# ADC14_356.0 register map
Vendor: Texas Instruments
Peripheral module from a debugger description file (folder MSP432).
Registers are 32-bit, read-write, no defined reset value unless marked. A register's access mark holds for its fields unless they carry their own. Offsets are as the file gives them; lines under a group give offsets from that group; [hi:lo] are bit positions; {n}, {i} and the like mark numbered series; 'fields as' and 'values as' point back to an identical list; <NAME> marks a mode.

## ADC14
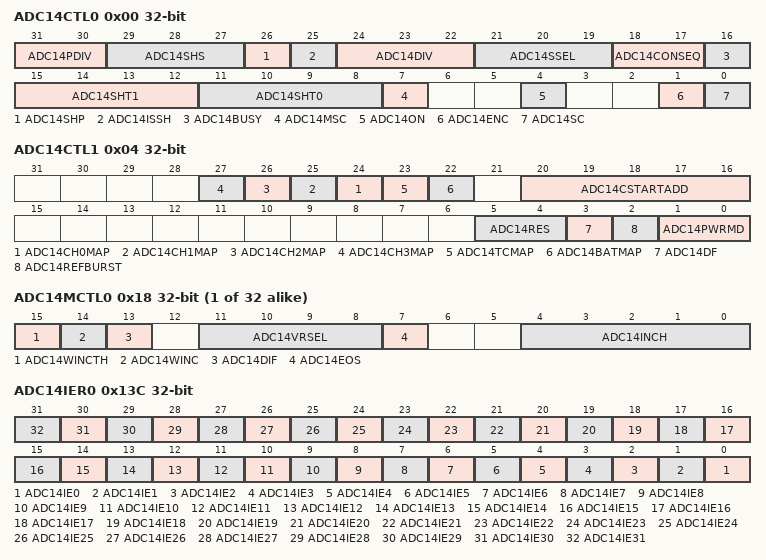
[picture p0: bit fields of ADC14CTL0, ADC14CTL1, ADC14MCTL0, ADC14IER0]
0x00 ADC14CTL0 access per field — Control 0 Register
  [31:30] ADC14PDIV rw — ADC14 predivider
    0=Predivide by 1; 1=Predivide by 4; 2=Predivide by 32; 3=Predivide by 64
  [29:27] ADC14SHS rw — ADC14 sample-and-hold source select
    0=ADC14SC bit; {v}=See device-specific data sheet for source (v=1..7)
  [26] ADC14SHP rw — ADC14 sample-and-hold pulse-mode select
    0=SAMPCON signal is sourced from the sample-input signal; 1=SAMPCON signal is sourced from the sampling timer
  [25] ADC14ISSH rw — ADC14 invert signal sample-and-hold
    0=OFF (The sample-input signal is not inverted); 1=ON (The sample-input signal is inverted)
  [24:22] ADC14DIV rw — ADC14 clock divider
    {v}={v+1} (v=0..7)
  [21:19] ADC14SSEL rw — ADC14 clock source select
    0=MODCLK; 1=SYSCLK; 2=ACLK; 3=MCLK; 4=SMCLK; 5=HSMCLK
  [18:17] ADC14CONSEQ rw — ADC14 conversion sequence mode select
    0=Single-channel, single-conversion; 1=Sequence-of-channels; 2=Repeat-single-channel; 3=Repeat-sequence-of-channels
  [16] ADC14BUSY ro
    0=IDLE (No operation is active); 1=BUSY (A sequence, sample, or conversion is active)
  [15:12] ADC14SHT1 rw — ADC14 sample-and-hold time
    0=4; 1=8; 2=16; 3=32; 4=64; 5=96; 6=128; 7=192
  [11:8] ADC14SHT0 rw — ADC14 sample-and-hold time
    0=4; 1=8; 2=16; 3=32; 4=64; 5=96; 6=128; 7=192
  [7] ADC14MSC rw — ADC14 multiple sample and conversion
    0=SINGLE (The sampling timer requires a rising edge of the SHI signal to trigger each sample-and-convert); 1=MULTIPLE (The first rising edge of the SHI signal triggers the sampling timer, but further sample-and-conversions are performed automatically as soon as the prior conversion is completed)
  [4] ADC14ON rw
    0=OFF (ADC14 off); 1=ON (ADC14 on. ADC core is ready to power up when a valid conversion is triggered.)
  [1] ADC14ENC rw — ADC14 enable conversion
    0=DISABLE (ADC14 disabled); 1=ENABLE (ADC14 enabled)
  [0] ADC14SC rw — ADC14 start conversion
    0=No sample-and-conversion-start; 1=START (Start sample-and-conversion)
0x04 ADC14CTL1 — Control 1 Register
  [n+24] ADC14CH{n}MAP (n=0..3) — Controls internal channel {n} selection to ADC input channel MAX-{n+2}
    0=OFF (ADC input channel internal {n} is not selected); 1=ON (ADC input channel internal {n} is selected for ADC input channel MAX-{n+2})
  [23] ADC14TCMAP — Controls temperature sensor ADC input channel selection
    0=OFF (ADC internal temperature sensor channel is not selected for ADC); 1=ON (ADC internal temperature sensor channel is selected for ADC input channel MAX-1)
  [22] ADC14BATMAP — Controls 1/2 AVCC ADC input channel selection
    0=OFF (ADC internal 1/2 x AVCC channel is not selected for ADC); 1=ON (ADC internal 1/2 x AVCC channel is selected for ADC input channel MAX)
  [20:16] ADC14CSTARTADD — ADC14 conversion start address
  [5:4] ADC14RES — ADC14 resolution
    0=8BIT (8 bit (9 clock cycle conversion time)); 1=10BIT (10 bit (11 clock cycle conversion time)); 2=12BIT (12 bit (14 clock cycle conversion time)); 3=14BIT (14 bit (16 clock cycle conversion time))
  [3] ADC14DF — ADC14 data read-back format
    0=UNSIGNED (Binary unsigned. Theoretically, for ADC14DIF = 0 and 14-bit mode, the analog input voltage - V(REF) results in 0000h, and the analog input voltage + V(REF) results in 3FFFh); 1=SIGNED (Signed binary (2s complement), left aligned. Theoretically, for ADC14DIF = 0 and 14-bit mode, the analog input voltage - V(REF) results in 8000h, and the analog input voltage + V(REF) results in 7FFCh)
  [2] ADC14REFBURST — ADC14 reference buffer burst
    0=ADC reference buffer on continuously; 1=ADC reference buffer on only during sample-and-conversion
  [1:0] ADC14PWRMD — ADC14 power modes
    0=Regular power mode for use with any resolution setting. Sample rate can be up to 1 Msps.; 2=Low-power mode for 12-bit, 10-bit, and 8-bit resolution settings. Sample rate must not exceed 200 ksps.
0x08 ADC14LO0 — Window Comparator Low Threshold 0 Register
  [15:0] ADC14LO0 — Low threshold 0
0x0C ADC14HI0 — Window Comparator High Threshold 0 Register
  [15:0] ADC14HI0 — High threshold 0
0x10 ADC14LO1 — Window Comparator Low Threshold 1 Register
  [15:0] ADC14LO1 — Low threshold 1
0x14 ADC14HI1 — Window Comparator High Threshold 1 Register
  [15:0] ADC14HI1 — High threshold 1
{0x18+4i} ADC14MCTL{i} (i=0..31) — Conversion Memory Control Register
  [15] ADC14WINCTH — Window comparator threshold register selection
    0=TH0 (Use window comparator thresholds 0, ADC14LO0 and ADC14HI0); 1=TH1 (Use window comparator thresholds 1, ADC14LO1 and ADC14HI1)
  [14] ADC14WINC — Comparator window enable
    0=DISABLE (Comparator window disabled); 1=ENABLE (Comparator window enabled)
  [13] ADC14DIF — Differential mode
    0=Single-ended mode enabled; 1=Differential mode enabled
  [11:8] ADC14VRSEL — Selects combinations of V(R+) and V(R-) sources
    0=V(R+) = AVCC, V(R-) = AVSS; 1=V(R+) = VREF buffered, V(R-) = AVSS; 14=V(R+) = VeREF+, V(R-) = VeREF-; 15=V(R+) = VeREF+ buffered, V(R-) = VeREF
  [7] ADC14EOS — End of sequence
    0=Not end of sequence; 1=End of sequence
  [4:0] ADC14INCH — Input channel select
    0=If ADC14DIF = 0: A0; If ADC14DIF = 1: Ain+ = A0, Ain- = A1; 1=If ADC14DIF = 0: A1; If ADC14DIF = 1: Ain+ = A0, Ain- = A1; 2=If ADC14DIF = 0: A2; If ADC14DIF = 1: Ain+ = A2, Ain- = A3; 3=If ADC14DIF = 0: A3; If ADC14DIF = 1: Ain+ = A2, Ain- = A3; 4=If ADC14DIF = 0: A4; If ADC14DIF = 1: Ain+ = A4, Ain- = A5; 5=If ADC14DIF = 0: A5; If ADC14DIF = 1: Ain+ = A4, Ain- = A5; 6=If ADC14DIF = 0: A6; If ADC14DIF = 1: Ain+ = A6, Ain- = A7; 7=If ADC14DIF = 0: A7; If ADC14DIF = 1: Ain+ = A6, Ain- = A7; 8=If ADC14DIF = 0: A8; If ADC14DIF = 1: Ain+ = A8, Ain- = A9; 9=If ADC14DIF = 0: A9; If ADC14DIF = 1: Ain+ = A8, Ain- = A9; 10=If ADC14DIF = 0: A10; If ADC14DIF = 1: Ain+ = A10, Ain- = A11; 11=If ADC14DIF = 0: A11; If ADC14DIF = 1: Ain+ = A10, Ain- = A11; 12=If ADC14DIF = 0: A12; If ADC14DIF = 1: Ain+ = A12, Ain- = A13; 13=If ADC14DIF = 0: A13; If ADC14DIF = 1: Ain+ = A12, Ain- = A13; 14=If ADC14DIF = 0: A14; If ADC14DIF = 1: Ain+ = A14, Ain- = A15; 15=If ADC14DIF = 0: A15; If ADC14DIF = 1: Ain+ = A14, Ain- = A15; 16=If ADC14DIF = 0: A16; If ADC14DIF = 1: Ain+ = A16, Ain- = A17; 17=If ADC14DIF = 0: A17; If ADC14DIF = 1: Ain+ = A16, Ain- = A17; 18=If ADC14DIF = 0: A18; If ADC14DIF = 1: Ain+ = A18, Ain- = A19; 19=If ADC14DIF = 0: A19; If ADC14DIF = 1: Ain+ = A18, Ain- = A19; 20=If ADC14DIF = 0: A20; If ADC14DIF = 1: Ain+ = A20, Ain- = A21; 21=If ADC14DIF = 0: A21; If ADC14DIF = 1: Ain+ = A20, Ain- = A21; 22=If ADC14DIF = 0: A22; If ADC14DIF = 1: Ain+ = A22, Ain- = A23; 23=If ADC14DIF = 0: A23; If ADC14DIF = 1: Ain+ = A22, Ain- = A23; 24=If ADC14DIF = 0: A24; If ADC14DIF = 1: Ain+ = A24, Ain- = A25; 25=If ADC14DIF = 0: A25; If ADC14DIF = 1: Ain+ = A24, Ain- = A25; 26=If ADC14DIF = 0: A26; If ADC14DIF = 1: Ain+ = A26, Ain- = A27; 27=If ADC14DIF = 0: A27; If ADC14DIF = 1: Ain+ = A26, Ain- = A27; 28=If ADC14DIF = 0: A28; If ADC14DIF = 1: Ain+ = A28, Ain- = A29; 29=If ADC14DIF = 0: A29; If ADC14DIF = 1: Ain+ = A28, Ain- = A29; 30=If ADC14DIF = 0: A30; If ADC14DIF = 1: Ain+ = A30, Ain- = A31; 31=If ADC14DIF = 0: A31; If ADC14DIF = 1: Ain+ = A30, Ain- = A31
{0x98+4i} ADC14MEM{i} (i=0..31) — Conversion Memory Register
  [15:0] Co{i}versio{i}_Results — Conversion Result
0x13C ADC14IER0 — Interrupt Enable 0 Register
  [all] fields
    0=DISABLE (Interrupt disabled); 1=ENABLE (Interrupt enabled)
  [n] ADC14IE{n} (n=0..31) — Interrupt enable
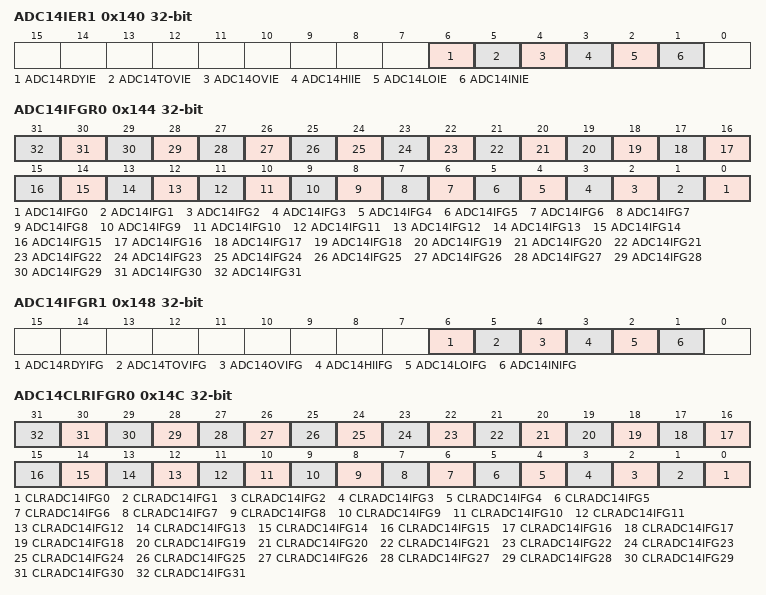
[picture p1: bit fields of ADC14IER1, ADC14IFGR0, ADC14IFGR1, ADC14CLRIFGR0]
0x140 ADC14IER1 — Interrupt Enable 1 Register
  [all] fields
    0=DISABLE (Interrupt disabled); 1=ENABLE (Interrupt enabled)
  [6] ADC14RDYIE — ADC14 local buffered reference ready interrupt enable
  [5] ADC14TOVIE — ADC14 conversion-time-overflow interrupt enable
  [4] ADC14OVIE — ADC14MEMx overflow-interrupt enable
  [3] ADC14HIIE — Interrupt enable for ADC14MEMx above comparator window
  [2] ADC14LOIE — Interrupt enable for ADC14MEMx below comparator window
  [1] ADC14INIE — Interrupt enable for ADC14MEMx within comparator window
0x144 ADC14IFGR0 ro — Interrupt Flag 0 Register
  [all] fields
    0=No interrupt pending; 1=Interrupt pending
  [n] ADC14IFG{n} (n=0..31) — ADC14MEM{n} interrupt flag
0x148 ADC14IFGR1 ro — Interrupt Flag 1 Register
  [all] fields
    0=No interrupt pending; 1=Interrupt pending
  [6] ADC14RDYIFG — ADC14 local buffered reference ready interrupt flag
  [5] ADC14TOVIFG — ADC14 conversion time overflow interrupt flag
  [4] ADC14OVIFG — ADC14MEMx overflow interrupt flag
  [3] ADC14HIIFG — Interrupt flag for ADC14MEMx above comparator window
  [2] ADC14LOIFG — Interrupt flag for ADC14MEMx below comparator window
  [1] ADC14INIFG — Interrupt flag for ADC14MEMx within comparator window
0x14C ADC14CLRIFGR0 — Clear Interrupt Flag 0 Register
  [all] fields
    0=no effect; 1=CLEAR (clear pending interrupt flag)
  [n] CLRADC14IFG{n} (n=0..31) — clear ADC14IFG{n}
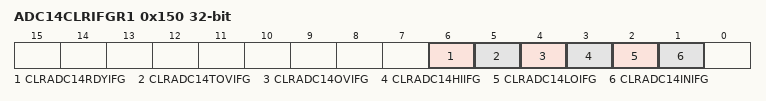
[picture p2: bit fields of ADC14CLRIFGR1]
0x150 ADC14CLRIFGR1 — Clear Interrupt Flag 1 Register
  [all] fields
    0=no effect; 1=clear pending interrupt flag
  [6] CLRADC14RDYIFG — clear ADC14RDYIFG
  [5] CLRADC14TOVIFG — clear ADC14TOVIFG
  [4] CLRADC14OVIFG — clear ADC14OVIFG
  [3] CLRADC14HIIFG — clear ADC14HIIFG
  [2] CLRADC14LOIFG — clear ADC14LOIFG
  [1] CLRADC14INIFG — clear ADC14INIFG
0x154 ADC14IV — Interrupt Vector Register
  [31:0] ADC14IV — ADC14 interrupt vector value
    0=NONE (No interrupt pending); 2=OVIFG (Interrupt Source: ADC14MEMx overflow; Interrupt Flag: ADC14OVIFG; Interrupt Priority: Highest); 4=TOVIFG (Interrupt Source: Conversion time overflow; Interrupt Flag: ADC14TOVIFG); 6=HIIFG (Interrupt Source: ADC14 window high interrupt flag; Interrupt Flag: ADC14HIIFG); 8=LOIFG (Interrupt Source: ADC14 window low interrupt flag; Interrupt Flag: ADC14LOIFG); 10=INIFG (Interrupt Source: ADC14 in-window interrupt flag; Interrupt Flag: ADC14INIFG); 12=IFG0 (Interrupt Source: ADC14MEM0 interrupt flag; Interrupt Flag: ADC14IFG0); 14=IFG1 (Interrupt Source: ADC14MEM1 interrupt flag; Interrupt Flag: ADC14IFG1); 16=IFG2 (Interrupt Source: ADC14MEM2 interrupt flag; Interrupt Flag: ADC14IFG2); 18=IFG3 (Interrupt Source: ADC14MEM3 interrupt flag; Interrupt Flag: ADC14IFG3); 20=IFG4 (Interrupt Source: ADC14MEM4 interrupt flag; Interrupt Flag: ADC14IFG4); 22=IFG5 (Interrupt Source: ADC14MEM5 interrupt flag; Interrupt Flag: ADC14IFG5); 24=IFG6 (Interrupt Source: ADC14MEM6 interrupt flag; Interrupt Flag: ADC14IFG6); 26=IFG7 (Interrupt Source: ADC14MEM7 interrupt flag; Interrupt Flag: ADC14IFG7); 28=IFG8 (Interrupt Source: ADC14MEM8 interrupt flag; Interrupt Flag: ADC14IFG8); 30=IFG9 (Interrupt Source: ADC14MEM9 interrupt flag; Interrupt Flag: ADC14IFG9); 32=IFG10 (Interrupt Source: ADC14MEM10 interrupt flag; Interrupt Flag: ADC14IFG10); 34=IFG11 (Interrupt Source: ADC14MEM11 interrupt flag; Interrupt Flag: ADC14IFG11); 36=IFG12 (Interrupt Source: ADC14MEM12 interrupt flag; Interrupt Flag: ADC14IFG12); 38=IFG13 (Interrupt Source: ADC14MEM13 interrupt flag; Interrupt Flag: ADC14IFG13); 40=IFG14 (Interrupt Source: ADC14MEM14 interrupt flag; Interrupt Flag: ADC14IFG14); 42=IFG15 (Interrupt Source: ADC14MEM15 interrupt flag; Interrupt Flag: ADC14IFG15); 44=IFG16 (Interrupt Source: ADC14MEM16 interrupt flag; Interrupt Flag: ADC14IFG16); 46=IFG17 (Interrupt Source: ADC14MEM17 interrupt flag; Interrupt Flag: ADC14IFG17); 48=IFG18 (Interrupt Source: ADC14MEM18 interrupt flag; Interrupt Flag: ADC14IFG18); 50=IFG19 (Interrupt Source: ADC14MEM19 interrupt flag; Interrupt Flag: ADC14IFG19); 52=IFG20 (Interrupt Source: ADC14MEM20 interrupt flag; Interrupt Flag: ADC14IFG20); 54=IFG21 (Interrupt Source: ADC14MEM22 interrupt flag; Interrupt Flag: ADC14IFG22); 56=IFG22 (Interrupt Source: ADC14MEM22 interrupt flag; Interrupt Flag: ADC14IFG22); 58=IFG23 (Interrupt Source: ADC14MEM23 interrupt flag; Interrupt Flag: ADC14IFG23); 60=IFG24 (Interrupt Source: ADC14MEM24 interrupt flag; Interrupt Flag: ADC14IFG24); 62=IFG25 (Interrupt Source: ADC14MEM25 interrupt flag; Interrupt Flag: ADC14IFG25); 64=IFG26 (Interrupt Source: ADC14MEM26 interrupt flag; Interrupt Flag: ADC14IFG26); 66=IFG27 (Interrupt Source: ADC14MEM27 interrupt flag; Interrupt Flag: ADC14IFG27); 68=IFG28 (Interrupt Source: ADC14MEM28 interrupt flag; Interrupt Flag: ADC14IFG28); 70=IFG29 (Interrupt Source: ADC14MEM29 interrupt flag; Interrupt Flag: ADC14IFG29); 72=IFG30 (Interrupt Source: ADC14MEM30 interrupt flag; Interrupt Flag: ADC14IFG30); 74=IFG31 (Interrupt Source: ADC14MEM31 interrupt flag; Interrupt Flag: ADC14IFG31); 76=RDYIFG (Interrupt Source: ADC14RDYIFG interrupt flag; Interrupt Flag: ADC14RDYIFG; Interrupt Priority: Lowest)
